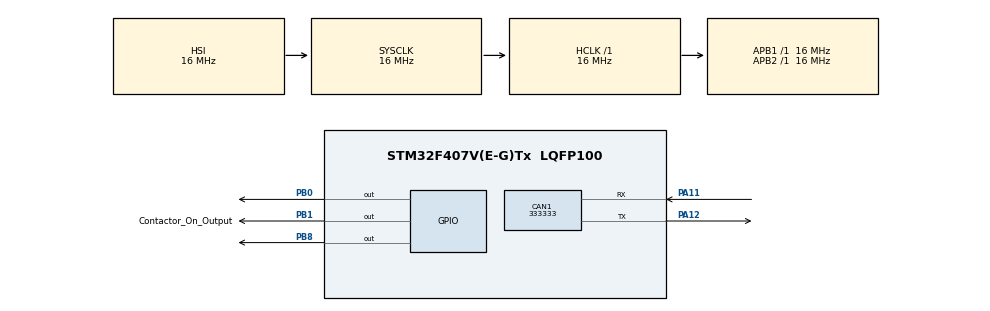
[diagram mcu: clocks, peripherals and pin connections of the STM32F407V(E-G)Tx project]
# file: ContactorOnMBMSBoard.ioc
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CAN1.CalculateBaudRate=333333
CAN1.CalculateTimeBit=3000
CAN1.CalculateTimeQuantum=1000.0
Mcu.Family=STM32F4
Mcu.Name=STM32F407V(E-G)Tx
Mcu.Package=LQFP100
NVIC.PriorityGroup=NVIC_PRIORITYGROUP_4
PA11.Mode=CAN_Activate
PA11.Signal=CAN1_RX
PA12.Mode=CAN_Activate
PA12.Signal=CAN1_TX
PB0.Signal=GPIO_Output
PB1.GPIO_Label=Contactor_On_Output
PB1.Signal=GPIO_Output
PB8.Signal=GPIO_Output
ProjectManager.HeapSize=0x200
ProjectManager.StackSize=0x400
ProjectManager.TargetToolchain=STM32CubeIDE
RCC.AHBFreq_Value=16000000
RCC.APB1Freq_Value=16000000
RCC.APB2Freq_Value=16000000
RCC.CortexFreq_Value=16000000
RCC.HSE_VALUE=25000000
RCC.HSI_VALUE=16000000
RCC.LSE_VALUE=32768
RCC.SYSCLKFreq_VALUE=16000000
RCC.VCOOutputFreq_Value=192000000
board=custom

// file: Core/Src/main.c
/* USER CODE BEGIN Header */
/**
  ******************************************************************************
  * @file           : main.c
  * @brief          : Main program body
  ******************************************************************************
  * @attention
  *
  * Copyright (c) 2025 STMicroelectronics.
  * All rights reserved.
  *
  * This software is licensed under terms that can be found in the LICENSE file
  * in the root directory of this software component.
  * If no LICENSE file comes with this software, it is provided AS-IS.
  *
  ******************************************************************************
  */
/* USER CODE END Header */
#include "main.h"

CAN_HandleTypeDef hcan1;

void SystemClock_Config(void);
static void MX_GPIO_Init(void);
static void MX_CAN1_Init(void);

int main(void)
{

  /* MCU Configuration--------------------------------------------------------*/

  /* Reset of all peripherals, Initializes the Flash interface and the Systick. */
  HAL_Init();

  /* Configure the system clock */
  SystemClock_Config();

  /* Initialize all configured peripherals */
  MX_GPIO_Init();
  MX_CAN1_Init();

  /* Infinite loop */
  /* USER CODE BEGIN WHILE */
  while (1)
  {
	  //Khai diode test for mbms board, 50% duty cycle @0.5Hz
	  //HAL_GPIO_TogglePin(GPIOB, GPIO_PIN_8);
	  //HAL_Delay(2000);

    /* USER CODE END WHILE */

  }
}

void SystemClock_Config(void)
{
  RCC_OscInitTypeDef RCC_OscInitStruct = {0};
  RCC_ClkInitTypeDef RCC_ClkInitStruct = {0};

  /** Configure the main internal regulator output voltage
  */
  __HAL_RCC_PWR_CLK_ENABLE();
  __HAL_PWR_VOLTAGESCALING_CONFIG(PWR_REGULATOR_VOLTAGE_SCALE1);

  /** Initializes the RCC Oscillators according to the specified parameters
  * in the RCC_OscInitTypeDef structure.
  */
  RCC_OscInitStruct.OscillatorType = RCC_OSCILLATORTYPE_HSI;
  RCC_OscInitStruct.HSIState = RCC_HSI_ON;
  RCC_OscInitStruct.HSICalibrationValue = RCC_HSICALIBRATION_DEFAULT;
  RCC_OscInitStruct.PLL.PLLState = RCC_PLL_NONE;
  if (HAL_RCC_OscConfig(&RCC_OscInitStruct) != HAL_OK)
  {
    Error_Handler();
  }

  /** Initializes the CPU, AHB and APB buses clocks
  */
  RCC_ClkInitStruct.ClockType = RCC_CLOCKTYPE_HCLK|RCC_CLOCKTYPE_SYSCLK
                              |RCC_CLOCKTYPE_PCLK1|RCC_CLOCKTYPE_PCLK2;
  RCC_ClkInitStruct.SYSCLKSource = RCC_SYSCLKSOURCE_HSI;
  RCC_ClkInitStruct.AHBCLKDivider = RCC_SYSCLK_DIV1;
  RCC_ClkInitStruct.APB1CLKDivider = RCC_HCLK_DIV1;
  RCC_ClkInitStruct.APB2CLKDivider = RCC_HCLK_DIV1;

  if (HAL_RCC_ClockConfig(&RCC_ClkInitStruct, FLASH_LATENCY_0) != HAL_OK)
  {
    Error_Handler();
  }
}

static void MX_CAN1_Init(void)
{

  hcan1.Instance = CAN1;
  hcan1.Init.Prescaler = 16;
  hcan1.Init.Mode = CAN_MODE_NORMAL;
  hcan1.Init.SyncJumpWidth = CAN_SJW_1TQ;
  hcan1.Init.TimeSeg1 = CAN_BS1_1TQ;
  hcan1.Init.TimeSeg2 = CAN_BS2_1TQ;
  hcan1.Init.TimeTriggeredMode = DISABLE;
  hcan1.Init.AutoBusOff = DISABLE;
  hcan1.Init.AutoWakeUp = DISABLE;
  hcan1.Init.AutoRetransmission = DISABLE;
  hcan1.Init.ReceiveFifoLocked = DISABLE;
  hcan1.Init.TransmitFifoPriority = DISABLE;
  if (HAL_CAN_Init(&hcan1) != HAL_OK)
  {
    Error_Handler();
  }

}

static void MX_GPIO_Init(void)
{
  GPIO_InitTypeDef GPIO_InitStruct = {0};

  /* GPIO Ports Clock Enable */
  __HAL_RCC_GPIOB_CLK_ENABLE();
  __HAL_RCC_GPIOA_CLK_ENABLE();

  /*Configure GPIO pin Output Level */
  HAL_GPIO_WritePin(GPIOB, GPIO_PIN_0|Contactor_On_Output_Pin|GPIO_PIN_8, GPIO_PIN_RESET);

  /*Configure GPIO pins : PB0 Contactor_On_Output_Pin PB8 */
  GPIO_InitStruct.Pin = GPIO_PIN_0|Contactor_On_Output_Pin|GPIO_PIN_8;
  GPIO_InitStruct.Mode = GPIO_MODE_OUTPUT_PP;
  GPIO_InitStruct.Pull = GPIO_NOPULL;
  GPIO_InitStruct.Speed = GPIO_SPEED_FREQ_LOW;
  HAL_GPIO_Init(GPIOB, &GPIO_InitStruct);

}

void Error_Handler(void)
{
  __disable_irq();
  while (1)
  {
  }
}
